# afe_hart_reva register map
Registers are access not given, no defined reset value unless marked. A register's access mark holds for its fields unless they carry their own. Offsets are from the block's base; lines under a group give offsets from that group; [hi:lo] are bit positions; {n}, {i} and the like mark numbered series; 'fields as' and 'values as' point back to an identical list; <NAME> marks a mode.

## Memory map
0x4FD00000 AFE_HART size 0x200 — Analog Front End HART Registers on Stacked Die via SPI

## AFE_HART — Analog Front End HART Registers on Stacked Die via SPI
Base 0x4FD00000
0x1800003 CTRL — HART Control
  [0] ADM_TM_EN — Description not included
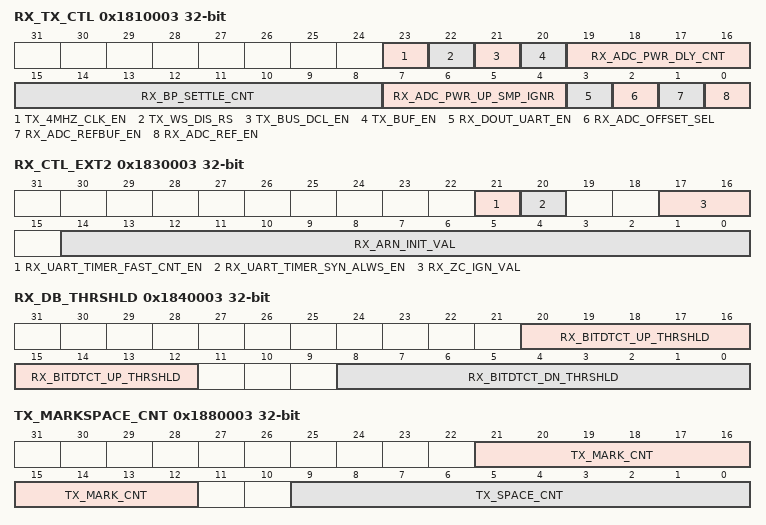
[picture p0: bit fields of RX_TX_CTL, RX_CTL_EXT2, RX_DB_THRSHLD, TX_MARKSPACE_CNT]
0x1810003 RX_TX_CTL — Control HART Transmit and Receive Functions
  [23] TX_4MHZ_CLK_EN — Description not included
  [22] TX_WS_DIS_RS — Description not included
  [21] TX_BUS_DCL_EN — Description not included
  [20] TX_BUF_EN — Description not included
  [19:16] RX_ADC_PWR_DLY_CNT — Description not included
  [15:8] RX_BP_SETTLE_CNT — Description not included
  [7:4] RX_ADC_PWR_UP_SMP_IGNR — Description not included
  [3] RX_DOUT_UART_EN — Description not included
  [2] RX_ADC_OFFSET_SEL — Description not included
  [1] RX_ADC_REFBUF_EN — Description not included
  [0] RX_ADC_REF_EN — Description not included
0x1820003 RX_CTL_EXT1 — Receive Control Extension Register 1
  [18:0] RX_AN_INIT_VAL — Description not included
0x1830003 RX_CTL_EXT2 — Receive Control Extension Register 2
  [21] RX_UART_TIMER_FAST_CNT_EN — Description not included
  [20] RX_UART_TIMER_SYN_ALWS_EN — Description not included
  [17:16] RX_ZC_IGN_VAL — Description not included
  [14:0] RX_ARN_INIT_VAL — Description not included
0x1840003 RX_DB_THRSHLD — Receive Bit-Detect/Demodulation Threshold
  [20:12] RX_BITDTCT_UP_THRSHLD — Description not included
  [8:0] RX_BITDTCT_DN_THRSHLD — Description not included
0x1850003 RX_CRD_UP_THRSHLD — Receive Carrier Detect Up Threshold Register
  [18:0] RX_CRD_UP_THRSHLD — Description not included
0x1860003 RX_CRD_DN_THRSHLD — Receive Carrier Detect Down Threshold Register
  [18:0] RX_CRD_DN_THRSHLD — Description not included
0x1870003 RX_CRD_DOUT_THRSHLD — Receive Carrier Detect DOUT Threshold
  [18:0] RX_CRD_DOUT_THRSHLD — Description not included
0x1880003 TX_MARKSPACE_CNT — Transmit Mark-Space Count Values
  [21:12] TX_MARK_CNT — Description not included
  [9:0] TX_SPACE_CNT — Description not included
0x1890003 STAT — Status Register
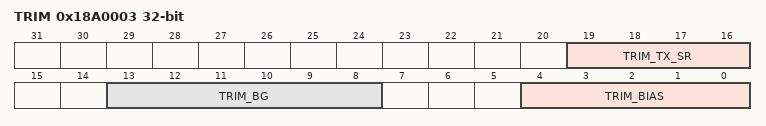
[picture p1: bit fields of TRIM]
0x18A0003 TRIM — HART Trim Register
  [19:16] TRIM_TX_SR — Description not included
  [13:8] TRIM_BG — Description not included
  [4:0] TRIM_BIAS — Description not included
0x18B0003 TM — Testmode
  [3] TM_BG_EN — Description not included
  [3] TM_VREF_EN — Description not included
  [1] TM_BIAS_EN — Description not included
  [0] TM_EN — Description not included
